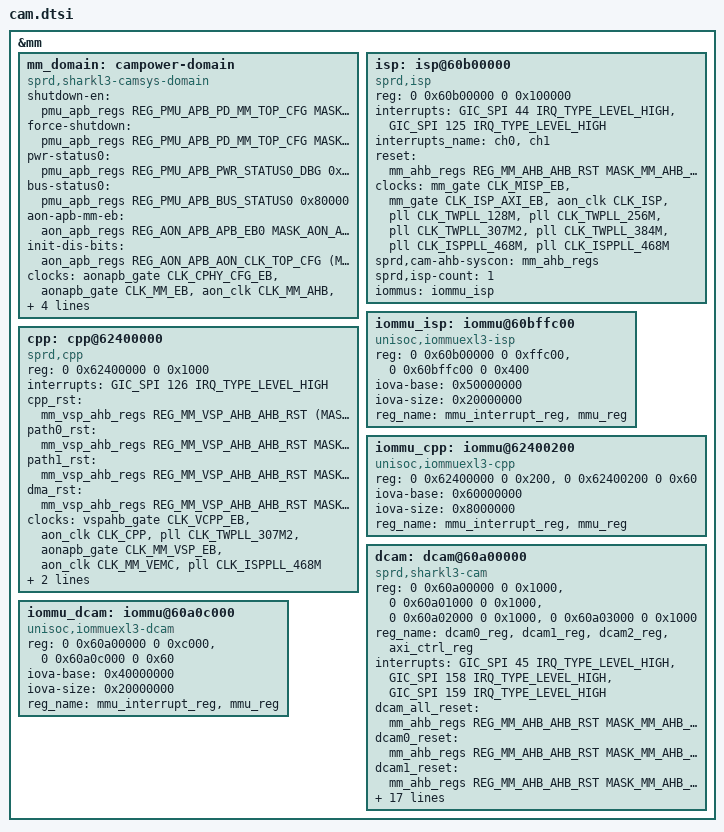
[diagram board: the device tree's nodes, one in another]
// SPDX-License-Identifier: (GPL-2.0+ OR MIT)
/*
 * Unisoc CAM dts file
 *
 * Copyright (C) 2020, Unisoc Inc.
 *
 */

&mm {
	mm_domain: campower-domain {
		compatible = "sprd,sharkl3-camsys-domain";
		shutdown-en = <&pmu_apb_regs
			REG_PMU_APB_PD_MM_TOP_CFG
			MASK_PMU_APB_PD_MM_TOP_AUTO_SHUTDOWN_EN>;
		force-shutdown = <&pmu_apb_regs
			REG_PMU_APB_PD_MM_TOP_CFG
			MASK_PMU_APB_PD_MM_TOP_FORCE_SHUTDOWN>;
		pwr-status0 = <&pmu_apb_regs
			REG_PMU_APB_PWR_STATUS0_DBG
			0xf8000000>;
		bus-status0 = <&pmu_apb_regs
			REG_PMU_APB_BUS_STATUS0
			0x80000>;
		aon-apb-mm-eb = <&aon_apb_regs
			REG_AON_APB_APB_EB0
			MASK_AON_APB_MM_EB>;
		init-dis-bits = <&aon_apb_regs
			REG_AON_APB_AON_CLK_TOP_CFG
			(MASK_AON_APB_CLK_MM_EMC_EB |
			MASK_AON_APB_CLK_MM_AHB_EB |
			MASK_AON_APB_CLK_SENSOR2_EB |
			MASK_AON_APB_CLK_DCAM_IF_EB |
			MASK_AON_APB_CLK_ISP_EB |
			MASK_AON_APB_CLK_JPG_EB |
			MASK_AON_APB_CLK_CPP_EB |
			MASK_AON_APB_CLK_SENSOR0_EB |
			MASK_AON_APB_CLK_SENSOR1_EB |
			MASK_AON_APB_CLK_MM_VSP_EMC_EB |
			MASK_AON_APB_CLK_MM_VSP_AHB_EB |
			MASK_AON_APB_CLK_VSP_EB)>;
		clock-names = "clk_cphy_cfg_gate_eb",
			"clk_mm_eb",
			"clk_mm_ahb",
			"clk_mm_ahb_parent",
			"clk_mm_emc",
			"clk_mm_emc_parent";
		clocks = <&aonapb_gate CLK_CPHY_CFG_EB>,
			<&aonapb_gate CLK_MM_EB>,
			<&aon_clk CLK_MM_AHB>,
			<&pll CLK_TWPLL_153M6>,
			<&aon_clk CLK_MM_EMC>,
			<&pll CLK_TWPLL_512M>;
		sprd,cam-ahb-syscon = <&mm_ahb_regs>;
		sprd,anlg_phy_g1_controller = <&anlg_phy_g1_regs>;
		#power-domain-cells = <0>;
		status = "okay";
	};

	isp: isp@60b00000 {
		compatible = "sprd,isp";
		reg = <0 0x60b00000 0 0x100000>;
		interrupts = <GIC_SPI 44 IRQ_TYPE_LEVEL_HIGH>,
			<GIC_SPI 125 IRQ_TYPE_LEVEL_HIGH>;
		interrupts_name = "ch0", "ch1";
		reset = <&mm_ahb_regs
				REG_MM_AHB_AHB_RST
				MASK_MM_AHB_ISP_LOG_SOFT_RST>;
		clock-names = "isp_eb", "isp_axi_eb",
			"isp_clk",
			"isp_clk_128m",
			"isp_clk_256m",
			"isp_clk_307m2",
			"isp_clk_384m",
			"isp_clk_468m",
			"isp_clk_parent";
		clocks = <&mm_gate CLK_MISP_EB>,
			<&mm_gate CLK_ISP_AXI_EB>,
			<&aon_clk CLK_ISP>,
			<&pll CLK_TWPLL_128M>,
			<&pll CLK_TWPLL_256M>,
			<&pll CLK_TWPLL_307M2>,
			<&pll CLK_TWPLL_384M>,
			<&pll CLK_ISPPLL_468M>,
			<&pll CLK_ISPPLL_468M>;
		sprd,cam-ahb-syscon = <&mm_ahb_regs>;
		sprd,isp-count = <1>;
		iommus = <&iommu_isp>;
		status = "okay";
	};

	iommu_isp: iommu@60bffc00 {
		compatible = "unisoc,iommuexl3-isp";
		/* sharkl3 isp need pagetalbe size */
		reg = <0 0x60b00000 0 0xffc00>,
			<0 0x60bffc00 0 0x400>;
		iova-base = <0x50000000>;
		iova-size = <0x20000000>;
		reg_name = "mmu_interrupt_reg","mmu_reg";
		status = "okay";
		#iommu-cells = <0>;
	};

	cpp: cpp@62400000 {
		compatible = "sprd,cpp";
		reg = <0 0x62400000 0 0x1000>;
		interrupts = <GIC_SPI 126 IRQ_TYPE_LEVEL_HIGH>;
		cpp_rst = <&mm_vsp_ahb_regs REG_MM_VSP_AHB_AHB_RST
			(MASK_MM_VSP_AHB_CPP_SOFT_RST |
			MASK_MM_VSP_AHB_CPP_PATH0_SOFT_RST |
			MASK_MM_VSP_AHB_CPP_PATH1_SOFT_RST |
			MASK_MM_VSP_AHB_CPP_DMA_SOFT_RST)>;
		path0_rst = <&mm_vsp_ahb_regs REG_MM_VSP_AHB_AHB_RST
			MASK_MM_VSP_AHB_CPP_PATH0_SOFT_RST>;
		path1_rst = <&mm_vsp_ahb_regs REG_MM_VSP_AHB_AHB_RST
			MASK_MM_VSP_AHB_CPP_PATH1_SOFT_RST>;
		dma_rst = <&mm_vsp_ahb_regs REG_MM_VSP_AHB_AHB_RST
			MASK_MM_VSP_AHB_CPP_DMA_SOFT_RST>;
		clock-names = "cpp_eb",
			"cpp_clk",
			"cpp_clk_parent",
			"clk_mm_vsp_eb",
			"clk_mm_vsp_emc",
			"clk_mm_vsp_emc_parent";
		clocks = <&vspahb_gate CLK_VCPP_EB>,
			<&aon_clk CLK_CPP>,
			<&pll CLK_TWPLL_307M2>,
			<&aonapb_gate CLK_MM_VSP_EB>,
			<&aon_clk CLK_MM_VEMC>,
			<&pll CLK_ISPPLL_468M>;
		iommus = <&iommu_cpp>;
		power-domains = <&vsp_pd>;
		status = "okay";
	};

	iommu_cpp: iommu@62400200 {
		compatible = "unisoc,iommuexl3-cpp";
		reg = <0 0x62400000 0 0x200>,
			<0 0x62400200 0 0x60>;
		iova-base = <0x60000000>;
		iova-size = <0x8000000>;
		reg_name = "mmu_interrupt_reg","mmu_reg";
		status = "okay";
		#iommu-cells = <0>;
	};

	dcam: dcam@60a00000 {
		compatible = "sprd,sharkl3-cam";
		reg = <0 0x60a00000 0 0x1000>,
			<0 0x60a01000 0 0x1000>,
			<0 0x60a02000 0 0x1000>,
			<0 0x60a03000 0 0x1000>;
		reg_name = "dcam0_reg","dcam1_reg",
			"dcam2_reg","axi_ctrl_reg";
		interrupts = <GIC_SPI 45 IRQ_TYPE_LEVEL_HIGH>,
			<GIC_SPI 158 IRQ_TYPE_LEVEL_HIGH>,
			<GIC_SPI 159 IRQ_TYPE_LEVEL_HIGH>;
		interrupt-names = "dcam0", "dcam1",
			"dcam2";
		dcam_all_reset = <&mm_ahb_regs REG_MM_AHB_AHB_RST
			MASK_MM_AHB_DCAM_ALL_SOFT_RST>;
		dcam0_reset = <&mm_ahb_regs REG_MM_AHB_AHB_RST
			MASK_MM_AHB_DCAM0_SOFT_RST>;
		dcam1_reset = <&mm_ahb_regs REG_MM_AHB_AHB_RST
			MASK_MM_AHB_DCAM1_SOFT_RST>;
		dcam2_reset = <&mm_ahb_regs REG_MM_AHB_AHB_RST
			MASK_MM_AHB_DCAM2_SOFT_RST>;
		clock-names = "dcam_eb",
			"dcam_axi_eb",
			"clk_cphy_cfg_gate_eb",
			"clk_mm_eb",
			"clk_mm_ahb",
			"clk_mm_ahb_parent",
			"clk_mm_emc",
			"clk_mm_emc_parent",
			"dcam_clk",
			"dcam_clk_256m",
			"dcam_clk_307m2",
			"dcam_clk_384m",
			"dcam_clk_parent",
			"dcam_bpc_clk",
			"dcam_bpc_clk_parent";
		clocks = <&mm_gate CLK_MDCAM_EB>,
			<&mm_gate CLK_DCAM_AXI_EB>,
			<&aonapb_gate CLK_CPHY_CFG_EB>,
			<&aonapb_gate CLK_MM_EB>,
			<&aon_clk CLK_MM_AHB>,
			<&pll CLK_TWPLL_153M6>,
			<&aon_clk CLK_MM_EMC>,
			<&pll CLK_TWPLL_512M>,
			<&aon_clk CLK_DCAM_IF>,
			<&pll CLK_TWPLL_256M>,
			<&pll CLK_TWPLL_307M2>,
			<&pll CLK_TWPLL_384M>,
			<&pll CLK_TWPLL_384M>,
			<&aon_clk CLK_BPC>,
			<&dpll CLK_DPLL0_622M3>;
		sprd,cam-ahb-syscon = <&mm_ahb_regs>;
		sprd,isp = <&isp>;
		sprd,dcam-count = <3>;
		sprd,project-id = <0>;
		iommus = <&iommu_dcam>;
		power-domains = <&mm_domain>;
		status = "okay";
	};

	iommu_dcam: iommu@60a0c000 {
		compatible = "unisoc,iommuexl3-dcam";
		reg = <0 0x60a00000 0 0xc000>,
			<0 0x60a0c000 0 0x60>;
		iova-base = <0x40000000>;
		iova-size = <0x20000000>;
		reg_name = "mmu_interrupt_reg", "mmu_reg";
		status = "okay";
		#iommu-cells = <0>;
	};
};
